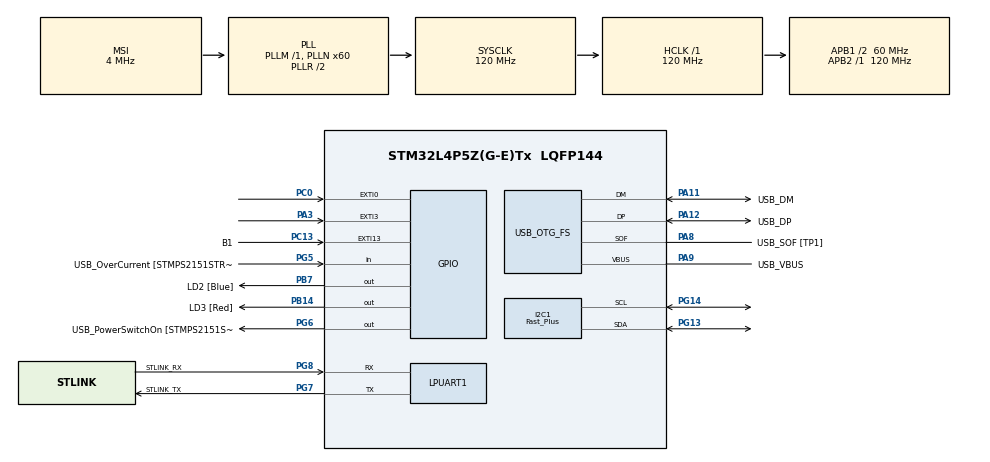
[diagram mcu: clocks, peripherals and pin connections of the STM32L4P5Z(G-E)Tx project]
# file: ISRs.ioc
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I2C1.I2C_Speed_Mode=I2C_Fast_Plus
I2C1.Timing=0x00200A26
Mcu.Family=STM32L4
Mcu.Name=STM32L4P5Z(G-E)Tx
Mcu.Package=LQFP144
NVIC.EXTI0_IRQn=true\:0\:0\:false\:false\:true\:true\:true
NVIC.EXTI3_IRQn=true\:0\:0\:false\:false\:true\:true\:true
NVIC.PriorityGroup=NVIC_PRIORITYGROUP_4
PA10.GPIO_Label=USB_ID
PA10.Signal=USB_OTG_FS_ID
PA11.GPIO_Label=USB_DM
PA11.Mode=Device_Only
PA11.Signal=USB_OTG_FS_DM
PA12.GPIO_Label=USB_DP
PA12.Mode=Device_Only
PA12.Signal=USB_OTG_FS_DP
PA13\ (JTMS/SWDIO).GPIO_Label=TMS
PA13\ (JTMS/SWDIO).Mode=Trace_Asynchronous_SW
PA13\ (JTMS/SWDIO).Signal=SYS_JTMS-SWDIO
PA14\ (JTCK/SWCLK).GPIO_Label=TCK
PA14\ (JTCK/SWCLK).Mode=Trace_Asynchronous_SW
PA14\ (JTCK/SWCLK).Signal=SYS_JTCK-SWCLK
PA3.GPIO_ModeDefaultEXTI=GPIO_MODE_IT_RISING
PA3.GPIO_PuPd=GPIO_PULLDOWN
PA3.Signal=GPXTI3
PA8.GPIO_Label=USB_SOF [TP1]
PA8.Mode=Activate_SOF_FS
PA8.Signal=USB_OTG_FS_SOF
PA9.GPIO_Label=USB_VBUS
PA9.Mode=Activate_VBUS
PA9.Signal=USB_OTG_FS_VBUS
PB14.GPIO_Label=LD3 [Red]
PB14.Signal=GPIO_Output
PB3\ (JTDO/TRACESWO).GPIO_Label=SWO
PB3\ (JTDO/TRACESWO).Mode=Trace_Asynchronous_SW
PB3\ (JTDO/TRACESWO).Signal=SYS_JTDO-SWO
PB7.GPIO_Label=LD2 [Blue]
PB7.Signal=GPIO_Output
PC0.GPIO_PuPd=GPIO_PULLDOWN
PC0.Signal=GPXTI0
PC13.GPIO_Label=B1
PC13.Signal=GPXTI13
PC14-OSC32_IN\ (PC14).Mode=LSE-External-Oscillator
PC14-OSC32_IN\ (PC14).Signal=RCC_OSC32_IN
PC15-OSC32_OUT\ (PC15).Mode=LSE-External-Oscillator
PC15-OSC32_OUT\ (PC15).Signal=RCC_OSC32_OUT
PG13.GPIO_Speed=GPIO_SPEED_FREQ_VERY_HIGH
PG13.Mode=I2C
PG13.Signal=I2C1_SDA
PG14.GPIO_Speed=GPIO_SPEED_FREQ_VERY_HIGH
PG14.Mode=I2C
PG14.Signal=I2C1_SCL
PG5.GPIO_Label=USB_OverCurrent [STMPS2151STR_FAULT]
PG5.Signal=GPIO_Input
PG6.GPIO_Label=USB_PowerSwitchOn [STMPS2151STR_En]
PG6.Signal=GPIO_Output
PG7.GPIO_Label=STLINK_TX
PG7.Mode=Asynchronous
PG7.Signal=LPUART1_TX
PG8.GPIO_Label=STLINK_RX
PG8.Mode=Asynchronous
PG8.Signal=LPUART1_RX
PH0-OSC_IN\ (PH0).Mode=HSE-External-Oscillator
PH0-OSC_IN\ (PH0).Signal=RCC_OSC_IN
PH1-OSC_OUT\ (PH1).Mode=HSE-External-Oscillator
PH1-OSC_OUT\ (PH1).Signal=RCC_OSC_OUT
ProjectManager.HeapSize=0x200
ProjectManager.StackSize=0x400
ProjectManager.TargetToolchain=STM32CubeIDE
RCC.48MHZClocksFreq_Value=24000000
RCC.ADCFreq_Value=48000000
RCC.AHBFreq_Value=120000000
RCC.APB1CLKDivider=RCC_HCLK_DIV2
RCC.APB1Freq_Value=60000000
RCC.APB1TimFreq_Value=120000000
RCC.APB2Freq_Value=120000000
RCC.APB2TimFreq_Value=120000000
RCC.CortexFreq_Value=120000000
RCC.HCLKFreq_Value=120000000
RCC.HSE_VALUE=8000000
RCC.HSI48_VALUE=48000000
RCC.HSI_VALUE=16000000
RCC.MSI_VALUE=4000000
RCC.PLLMUL=RCC_PLL_MUL9
RCC.PLLN=60
RCC.PLLSAI1N=24
RCC.PRESCALERUSB=RCC_USBCLKSOURCE_PLL_DIV1_5
RCC.SYSCLKFreq_VALUE=120000000
RCC.SYSCLKSource=RCC_SYSCLKSOURCE_PLLCLK
RCC.SYSCLKSourceVirtual=RCC_SYSCLKSOURCE_PLLCLK
RCC.USBFreq_Value=48000000
RCC.VCOOutputFreq_Value=240000000
USB_OTG_FS.VirtualMode=Device_Only
board=NUCLEO-L4P5ZG

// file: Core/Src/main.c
/* USER CODE BEGIN Header */
/**
  ******************************************************************************
  * @file           : main.c
  * @brief          : Main program body
  ******************************************************************************
  * @attention
  *
  * <h2><center>&copy; Copyright (c) 2020 STMicroelectronics.
  * All rights reserved.</center></h2>
  *
  * This software component is licensed by ST under BSD 3-Clause license,
  * the "License"; You may not use this file except in compliance with the
  * License. You may obtain a copy of the License at:
  *                        opensource.org/licenses/BSD-3-Clause
  *
  ******************************************************************************
  */
/* USER CODE END Header */

#include "main.h"

/* USER CODE BEGIN Includes */
#include "oled.h"
#include <stdint.h>
/* USER CODE END Includes */

I2C_HandleTypeDef hi2c1;

UART_HandleTypeDef hlpuart1;
UART_HandleTypeDef huart1;

PCD_HandleTypeDef hpcd_USB_OTG_FS;

void SystemClock_Config(void);
static void MX_GPIO_Init(void);
static void MX_LPUART1_UART_Init(void);
static void MX_USB_OTG_FS_PCD_Init(void);
static void MX_I2C1_Init(void);

int main(void)
{

  /* MCU Configuration--------------------------------------------------------*/

  /* Reset of all peripherals, Initializes the Flash interface and the Systick. */
  HAL_Init();

  /* Configure the system clock */
  SystemClock_Config();

  /* Initialize all configured peripherals */
  MX_GPIO_Init();
  MX_LPUART1_UART_Init();
  MX_USB_OTG_FS_PCD_Init();
  MX_I2C1_Init();
  /* USER CODE BEGIN 2 */

  /*Initialize OLED Settings  */
  OLED_init();
  /* USER CODE END 2 */

  /* Infinite loop */
  /* USER CODE BEGIN WHILE */
  while (1)
  {

	  /* Print animation  */
	 printGif();
    /* USER CODE END WHILE */

  }
}

void SystemClock_Config(void)
{
  RCC_OscInitTypeDef RCC_OscInitStruct = {0};
  RCC_ClkInitTypeDef RCC_ClkInitStruct = {0};
  RCC_PeriphCLKInitTypeDef PeriphClkInit = {0};

  /** Configure the main internal regulator output voltage
  */
  if (HAL_PWREx_ControlVoltageScaling(PWR_REGULATOR_VOLTAGE_SCALE1_BOOST) != HAL_OK)
  {
    Error_Handler();
  }
  /** Configure LSE Drive Capability
  */
  HAL_PWR_EnableBkUpAccess();
  __HAL_RCC_LSEDRIVE_CONFIG(RCC_LSEDRIVE_LOW);
  /** Initializes the CPU, AHB and APB busses clocks
  */
  RCC_OscInitStruct.OscillatorType = RCC_OSCILLATORTYPE_LSE|RCC_OSCILLATORTYPE_MSI;
  RCC_OscInitStruct.LSEState = RCC_LSE_ON;
  RCC_OscInitStruct.MSIState = RCC_MSI_ON;
  RCC_OscInitStruct.MSICalibrationValue = 0;
  RCC_OscInitStruct.MSIClockRange = RCC_MSIRANGE_6;
  RCC_OscInitStruct.PLL.PLLState = RCC_PLL_ON;
  RCC_OscInitStruct.PLL.PLLSource = RCC_PLLSOURCE_MSI;
  RCC_OscInitStruct.PLL.PLLM = 1;
  RCC_OscInitStruct.PLL.PLLN = 60;
  RCC_OscInitStruct.PLL.PLLP = RCC_PLLP_DIV7;
  RCC_OscInitStruct.PLL.PLLQ = RCC_PLLQ_DIV2;
  RCC_OscInitStruct.PLL.PLLR = RCC_PLLR_DIV2;
  if (HAL_RCC_OscConfig(&RCC_OscInitStruct) != HAL_OK)
  {
    Error_Handler();
  }
  /** Initializes the CPU, AHB and APB busses clocks
  */
  RCC_ClkInitStruct.ClockType = RCC_CLOCKTYPE_HCLK|RCC_CLOCKTYPE_SYSCLK
                              |RCC_CLOCKTYPE_PCLK1|RCC_CLOCKTYPE_PCLK2;
  RCC_ClkInitStruct.SYSCLKSource = RCC_SYSCLKSOURCE_PLLCLK;
  RCC_ClkInitStruct.AHBCLKDivider = RCC_SYSCLK_DIV1;
  RCC_ClkInitStruct.APB1CLKDivider = RCC_HCLK_DIV2;
  RCC_ClkInitStruct.APB2CLKDivider = RCC_HCLK_DIV1;

  if (HAL_RCC_ClockConfig(&RCC_ClkInitStruct, FLASH_LATENCY_5) != HAL_OK)
  {
    Error_Handler();
  }
  PeriphClkInit.PeriphClockSelection = RCC_PERIPHCLK_LPUART1|RCC_PERIPHCLK_I2C1
                              |RCC_PERIPHCLK_USB;
  PeriphClkInit.Lpuart1ClockSelection = RCC_LPUART1CLKSOURCE_PCLK1;
  PeriphClkInit.I2c1ClockSelection = RCC_I2C1CLKSOURCE_PCLK1;
  PeriphClkInit.UsbClockSelection = RCC_USBCLKSOURCE_PLLSAI1;
  PeriphClkInit.PLLSAI1.PLLSAI1Source = RCC_PLLSOURCE_MSI;
  PeriphClkInit.PLLSAI1.PLLSAI1M = 1;
  PeriphClkInit.PLLSAI1.PLLSAI1N = 24;
  PeriphClkInit.PLLSAI1.PLLSAI1P = RCC_PLLP_DIV7;
  PeriphClkInit.PLLSAI1.PLLSAI1Q = RCC_PLLQ_DIV2;
  PeriphClkInit.PLLSAI1.PLLSAI1R = RCC_PLLR_DIV2;
  PeriphClkInit.PLLSAI1.PLLSAI1ClockOut = RCC_PLLSAI1_48M2CLK;
  if (HAL_RCCEx_PeriphCLKConfig(&PeriphClkInit) != HAL_OK)
  {
    Error_Handler();
  }
  /** Enable MSI Auto calibration
  */
  HAL_RCCEx_EnableMSIPLLMode();
}

static void MX_I2C1_Init(void)
{

  hi2c1.Instance = I2C1;
  hi2c1.Init.Timing = 0x00200A26;
  hi2c1.Init.OwnAddress1 = 0;
  hi2c1.Init.AddressingMode = I2C_ADDRESSINGMODE_7BIT;
  hi2c1.Init.DualAddressMode = I2C_DUALADDRESS_DISABLE;
  hi2c1.Init.OwnAddress2 = 0;
  hi2c1.Init.OwnAddress2Masks = I2C_OA2_NOMASK;
  hi2c1.Init.GeneralCallMode = I2C_GENERALCALL_DISABLE;
  hi2c1.Init.NoStretchMode = I2C_NOSTRETCH_DISABLE;
  if (HAL_I2C_Init(&hi2c1) != HAL_OK)
  {
    Error_Handler();
  }
  /** Configure Analogue filter
  */
  if (HAL_I2CEx_ConfigAnalogFilter(&hi2c1, I2C_ANALOGFILTER_ENABLE) != HAL_OK)
  {
    Error_Handler();
  }
  /** Configure Digital filter
  */
  if (HAL_I2CEx_ConfigDigitalFilter(&hi2c1, 0) != HAL_OK)
  {
    Error_Handler();
  }
  /** I2C Fast mode Plus enable
  */
  HAL_I2CEx_EnableFastModePlus(I2C_FASTMODEPLUS_I2C1);

}

static void MX_LPUART1_UART_Init(void)
{

  hlpuart1.Instance = LPUART1;
  hlpuart1.Init.BaudRate = 209700;
  hlpuart1.Init.WordLength = UART_WORDLENGTH_7B;
  hlpuart1.Init.StopBits = UART_STOPBITS_1;
  hlpuart1.Init.Parity = UART_PARITY_NONE;
  hlpuart1.Init.Mode = UART_MODE_TX_RX;
  hlpuart1.Init.HwFlowCtl = UART_HWCONTROL_NONE;
  hlpuart1.Init.OneBitSampling = UART_ONE_BIT_SAMPLE_DISABLE;
  hlpuart1.Init.ClockPrescaler = UART_PRESCALER_DIV1;
  hlpuart1.AdvancedInit.AdvFeatureInit = UART_ADVFEATURE_NO_INIT;
  hlpuart1.FifoMode = UART_FIFOMODE_DISABLE;
  if (HAL_UART_Init(&hlpuart1) != HAL_OK)
  {
    Error_Handler();
  }
  if (HAL_UARTEx_SetTxFifoThreshold(&hlpuart1, UART_TXFIFO_THRESHOLD_1_8) != HAL_OK)
  {
    Error_Handler();
  }
  if (HAL_UARTEx_SetRxFifoThreshold(&hlpuart1, UART_RXFIFO_THRESHOLD_1_8) != HAL_OK)
  {
    Error_Handler();
  }
  if (HAL_UARTEx_DisableFifoMode(&huart1) != HAL_OK)
  {
    Error_Handler();
  }

}

static void MX_USB_OTG_FS_PCD_Init(void)
{

  hpcd_USB_OTG_FS.Instance = USB_OTG_FS;
  hpcd_USB_OTG_FS.Init.dev_endpoints = 6;
  hpcd_USB_OTG_FS.Init.phy_itface = PCD_PHY_EMBEDDED;
  hpcd_USB_OTG_FS.Init.Sof_enable = ENABLE;
  hpcd_USB_OTG_FS.Init.low_power_enable = DISABLE;
  hpcd_USB_OTG_FS.Init.lpm_enable = DISABLE;
  hpcd_USB_OTG_FS.Init.battery_charging_enable = ENABLE;
  hpcd_USB_OTG_FS.Init.use_dedicated_ep1 = DISABLE;
  hpcd_USB_OTG_FS.Init.vbus_sensing_enable = ENABLE;
  if (HAL_PCD_Init(&hpcd_USB_OTG_FS) != HAL_OK)
  {
    Error_Handler();
  }

}

static void MX_GPIO_Init(void)
{
  GPIO_InitTypeDef GPIO_InitStruct = {0};

  /* GPIO Ports Clock Enable */
  __HAL_RCC_GPIOC_CLK_ENABLE();
  __HAL_RCC_GPIOH_CLK_ENABLE();
  __HAL_RCC_GPIOA_CLK_ENABLE();
  __HAL_RCC_GPIOB_CLK_ENABLE();
  __HAL_RCC_GPIOG_CLK_ENABLE();
  HAL_PWREx_EnableVddIO2();

  /*Configure GPIO pin Output Level */
  HAL_GPIO_WritePin(GPIOB, LD3_Pin|LD2_Pin, GPIO_PIN_RESET);

  /*Configure GPIO pin Output Level */
  HAL_GPIO_WritePin(USB_PowerSwitchOn_GPIO_Port, USB_PowerSwitchOn_Pin, GPIO_PIN_RESET);

  /*Configure GPIO pin : B1_Pin */
  GPIO_InitStruct.Pin = B1_Pin;
  GPIO_InitStruct.Mode = GPIO_MODE_IT_RISING;
  GPIO_InitStruct.Pull = GPIO_NOPULL;
  HAL_GPIO_Init(B1_GPIO_Port, &GPIO_InitStruct);

  /*Configure GPIO pin : PC0 */
  GPIO_InitStruct.Pin = GPIO_PIN_0;
  GPIO_InitStruct.Mode = GPIO_MODE_IT_RISING;
  GPIO_InitStruct.Pull = GPIO_PULLDOWN;
  HAL_GPIO_Init(GPIOC, &GPIO_InitStruct);

  /*Configure GPIO pin : PA3 */
  GPIO_InitStruct.Pin = GPIO_PIN_3;
  GPIO_InitStruct.Mode = GPIO_MODE_IT_RISING;
  GPIO_InitStruct.Pull = GPIO_PULLDOWN;
  HAL_GPIO_Init(GPIOA, &GPIO_InitStruct);

  /*Configure GPIO pins : LD3_Pin LD2_Pin */
  GPIO_InitStruct.Pin = LD3_Pin|LD2_Pin;
  GPIO_InitStruct.Mode = GPIO_MODE_OUTPUT_PP;
  GPIO_InitStruct.Pull = GPIO_NOPULL;
  GPIO_InitStruct.Speed = GPIO_SPEED_FREQ_LOW;
  HAL_GPIO_Init(GPIOB, &GPIO_InitStruct);

  /*Configure GPIO pin : USB_OverCurrent_Pin */
  GPIO_InitStruct.Pin = USB_OverCurrent_Pin;
  GPIO_InitStruct.Mode = GPIO_MODE_INPUT;
  GPIO_InitStruct.Pull = GPIO_NOPULL;
  HAL_GPIO_Init(USB_OverCurrent_GPIO_Port, &GPIO_InitStruct);

  /*Configure GPIO pin : USB_PowerSwitchOn_Pin */
  GPIO_InitStruct.Pin = USB_PowerSwitchOn_Pin;
  GPIO_InitStruct.Mode = GPIO_MODE_OUTPUT_PP;
  GPIO_InitStruct.Pull = GPIO_NOPULL;
  GPIO_InitStruct.Speed = GPIO_SPEED_FREQ_LOW;
  HAL_GPIO_Init(USB_PowerSwitchOn_GPIO_Port, &GPIO_InitStruct);

  /* EXTI interrupt init*/
  HAL_NVIC_SetPriority(EXTI0_IRQn, 0, 0);
  HAL_NVIC_EnableIRQ(EXTI0_IRQn);

  HAL_NVIC_SetPriority(EXTI3_IRQn, 0, 0);
  HAL_NVIC_EnableIRQ(EXTI3_IRQn);

}

/* USER CODE BEGIN 4 */
/*Interrupt Service Routine */
void HAL_GPIO_EXTI_Callback(uint16_t GPIO_Pin)
{
	uint32_t i, j;

	if(GPIO_Pin == GPIO_PIN_0) //Run if the EXTI0 is enable
	{

		for( j = 0; j < 40; j++)
		{
			for(i = 0; i < 1000000; i++);
			HAL_GPIO_TogglePin(GPIOB, GPIO_PIN_7);  //User Led Blue

		}
	}
	else if(GPIO_Pin == GPIO_PIN_3) //Run if the EXTI3 is enable
	{

		for( j = 0; j < 40; j++)
		{
			for(i = 0; i < 1000000; i++);
			HAL_GPIO_TogglePin(GPIOB, GPIO_PIN_14); //User Led Red

		}

	}

}

/* USER CODE END 4 */

void Error_Handler(void)
{
}

/************************ (C) COPYRIGHT STMicroelectronics *****END OF FILE****/
